# DA14683 register map
Vendor: Dialog; Series: DA14683; File version: 1.2
CPU: CM0 r1p0, little endian, MPU, FPU, 3 interrupt priority bits
Registers are 16-bit, read-write, reset 0x0 unless marked. A register's access mark holds for its fields unless they carry their own. Offsets are from the block's base; [hi:lo] are bit positions; <NAME> marks a mode.

## SPI2 — SPI2 registers
Base 0x50001300
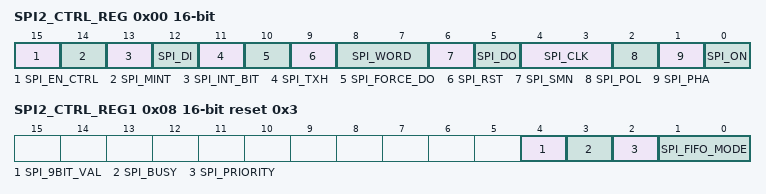
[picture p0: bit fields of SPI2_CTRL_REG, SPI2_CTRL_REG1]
0x00 SPI2_CTRL_REG — SPI control register 0
  [15] SPI_EN_CTRL — 0 = SPI_EN pin disabled in slave mode. Pin SPI_EN is don't care. 1 = SPI_EN pin enabled in slave mode.
  [14] SPI_MINT — 0 = Disable SPI_INT_BIT to ICU 1 = Enable SPI_INT_BIT to ICU. Note that the SPI_INT interrupt is shared with AD_INT interrupt
  [13] SPI_INT_BIT ro — 0 = RX Register or FIFO is empty. 1 = SPI interrupt. Data has been transmitted and receivedMust be reset by SW by writing to SPI_CLEAR_INT_REG.
  [12] SPI_DI ro — Returns the actual value of pin SPI_DIN (delayed with two internal SPI clock cycles)
  [11] SPI_TXH ro — 0 = TX-FIFO is not full, data can be written. 1 = TX-FIFO is full, data can not be written.
  [10] SPI_FORCE_DO — 0 = normal operation 1 = Force SPIDO output level to value of SPI_DO.
  [9] SPI_RST — 0 = normal operation 1 = Reset SPI. Same function as SPI_ON except that internal clock remain active.
  [8:7] SPI_WORD — 00 = 8 bits mode, only SPI_RX_TX_REG0 used 01 = 16 bit mode, only SPI_RX_TX_REG0 used 10 = 32 bits mode, SPI_RX_TX_REG0 & SPI_RX_TX_REG1 used 11 = 9 bits mode. Only valid in master mode.
  [6] SPI_SMN — Master/slave mode 0 = Master, 1 = Slave(SPI1 only)
  [5] SPI_DO — Pin SPI_DO output level when SPI is idle or when SPI_FORCE_DO=1
  [4:3] SPI_CLK — Select SPI_CLK clock output frequency in master mode: 00 = SPI_CLK / 8 01 = SPI_CLK / 4 10 = SPI_CLK / 2 11 = SPI_CLK / 14
  [2] SPI_POL — Select SPI_CLK polarity. 0 = SPI_CLK is initially low. 1 = SPI_CLK is initially high.
  [1] SPI_PHA — Select SPI_CLK phase. See functional timing diagrams in SPI chapter
  [0] SPI_ON — 0 = SPI Module switched off (power saving). Everything is reset except SPI_CTRL_REG0 and SPI_CTRL_REG1. When this bit is cleared the SPI will remain active in master mode until the shift register and holding register are both empty. 1 = SPI Module switched on. Should only be set after all control bits have their desired values. So two writes are needed!
0x02 SPI2_RX_TX_REG0 — SPI RX/TX register0
  [15:0] SPI_DATA0 wo — Write: SPI_TX_REG0 output register 0 (TX-FIFO) Read: SPI_RX_REG0 input register 0 (RX-FIFO) In 8 or 9 bits mode bits 15 to 8 are not used, they contain old data.
0x04 SPI2_RX_TX_REG1 — SPI RX/TX register1
  [15:0] SPI_DATA1 wo — Write: SPI_TX_REG1 output register 1 (MSB's of TX-FIFO) Read: SPI_RX_REG1 input register 1 (MSB's of RX-FIFO) In 8 or 9 or 16 bits mode bits this register is not used.
0x06 SPI2_CLEAR_INT_REG — SPI clear interrupt register
  [15:0] SPI_CLEAR_INT wo — Writing any value to this register will clear the SPI_CTRL_REG[SPI_INT_BIT] Reading returns 0.
0x08 SPI2_CTRL_REG1 reset 0x3 — SPI control register 1
  [4] SPI_9BIT_VAL — Determines the value of the first bit in 9 bits SPI mode.
  [3] SPI_BUSY ro — 0 = The SPI is not busy with a transfer. This means that either no TX-data is available or that the transfers have been suspended due to a full RX-FIFO. The SPIx_CTRL_REG0[SPI_INT_BIT] can be used to distinguish between these situations. 1 = The SPI is busy with a transfer.
  [2] SPI_PRIORITY — 0 = The SPI has low priority, the DMA request signals are reset after the corresponding acknowledge. 1 = The SPI has high priority, DMA request signals remain active until the FIFOS are filled/emptied, so the DMA holds the AHB bus.
  [1:0] SPI_FIFO_MODE — 0: TX-FIFO and RX-FIFO used (Bidirectional mode). 1: RX-FIFO used (Read Only Mode) TX-FIFO single depth, no flow control 2: TX-FIFO used (Write Only Mode), RX-FIFO single depth, no flow control 3: No FIFOs used (backwards compatible mode)

## TRNG — TRNG registers
Base 0x50005000
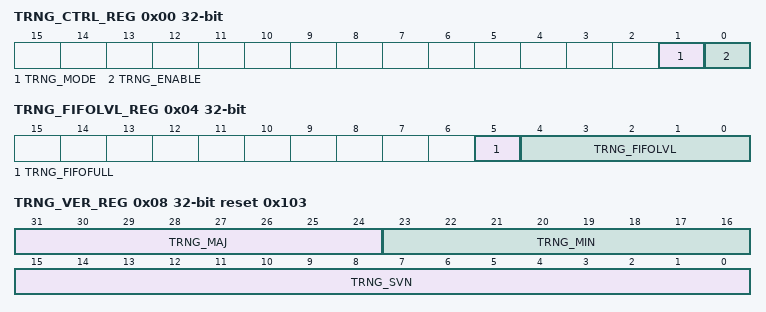
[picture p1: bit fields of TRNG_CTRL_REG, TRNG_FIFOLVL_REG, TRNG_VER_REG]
0x00 TRNG_CTRL_REG 32-bit — TRNG control register
  [1] TRNG_MODE — 0: select the TRNG with asynchronous free running oscillators (default) 1: select the pseudo-random generator with synchronous oscillators (for simulation purpose only)
  [0] TRNG_ENABLE — 0: Disable the TRNG 1: Enable the TRNG this signal is ignored when the FIFO is full
0x04 TRNG_FIFOLVL_REG 32-bit — TRNG FIFO level register
  [5] TRNG_FIFOFULL ro — 1:FIFO full indication. This bit is cleared if the FIFO is read.
  [4:0] TRNG_FIFOLVL ro — Number of 32 bit words of random data in the FIFO (max 31) until the FIFO is full. When it is 0 and TRNG_FIFOFULL is 1, it means the FIFO is full.
0x08 TRNG_VER_REG 32-bit reset 0x103 (reset mask 0x7FFFFFFF) — TRNG Version register
  [31:24] TRNG_MAJ ro — Major version number
  [23:16] TRNG_MIN ro — Minor version number
  [15:0] TRNG_SVN ro — SVN revision number

## WDOG — WDOG registers
Base 0x50003100
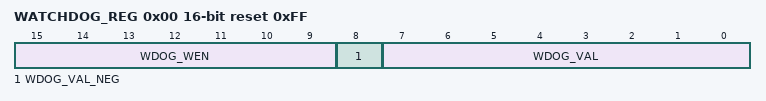
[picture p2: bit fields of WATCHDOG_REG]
0x00 WATCHDOG_REG reset 0xFF — Watchdog timer register.
  [15:9] WDOG_WEN wo — 0000.000 = Write enable for Watchdog timer else Write disable. This filter prevents unintentional presetting the watchdog with a SW run-away.
  [8] WDOG_VAL_NEG — 0 = Watchdog timer value is positive. 1 = Watchdog timer value is negative.
  [7:0] WDOG_VAL — Write: Watchdog timer reload value. Note that all bits 15-9 must be 0 to reload this register. Read: Actual Watchdog timer value. Decremented by 1 every 10.24 msec. Bit 8 indicates a negative counter value. 2, 1, 0, 1FF16, 1FE16 etc. An NMI or WDOG (SYS) reset is generated under the following conditions: If WATCHDOG_CTRL_REG[NMI_RST] = 0 then If WDOG_VAL = 0 -> NMI (Non Maskable Interrupt) if WDOG_VAL = 1F016 -> WDOG reset -> reload FF16 If WATCHDOG_CTRL_REG[NMI_RST] = 1 then if WDOG_VAL <= 0 -> WDOG reset -> reload FF16
0x02 WATCHDOG_CTRL_REG — Watchdog control register.
  [0] NMI_RST — 0 = Watchdog timer generates NMI at value 0, and WDOG (SYS) reset at <=-16. Timer can be frozen /resumed using SET_FREEZE_REG[FRZ_WDOG]/ RESET_FREEZE_REG[FRZ_WDOG]. 1 = Watchdog timer generates a WDOG (SYS) reset at value 0 and can not be frozen by Software. Note that this bit can only be set to 1 by SW and only be reset with a WDOG (SYS) reset or SW reset. The watchdog is always frozen when the Cortex-M0 is halted in DEBUG State.
